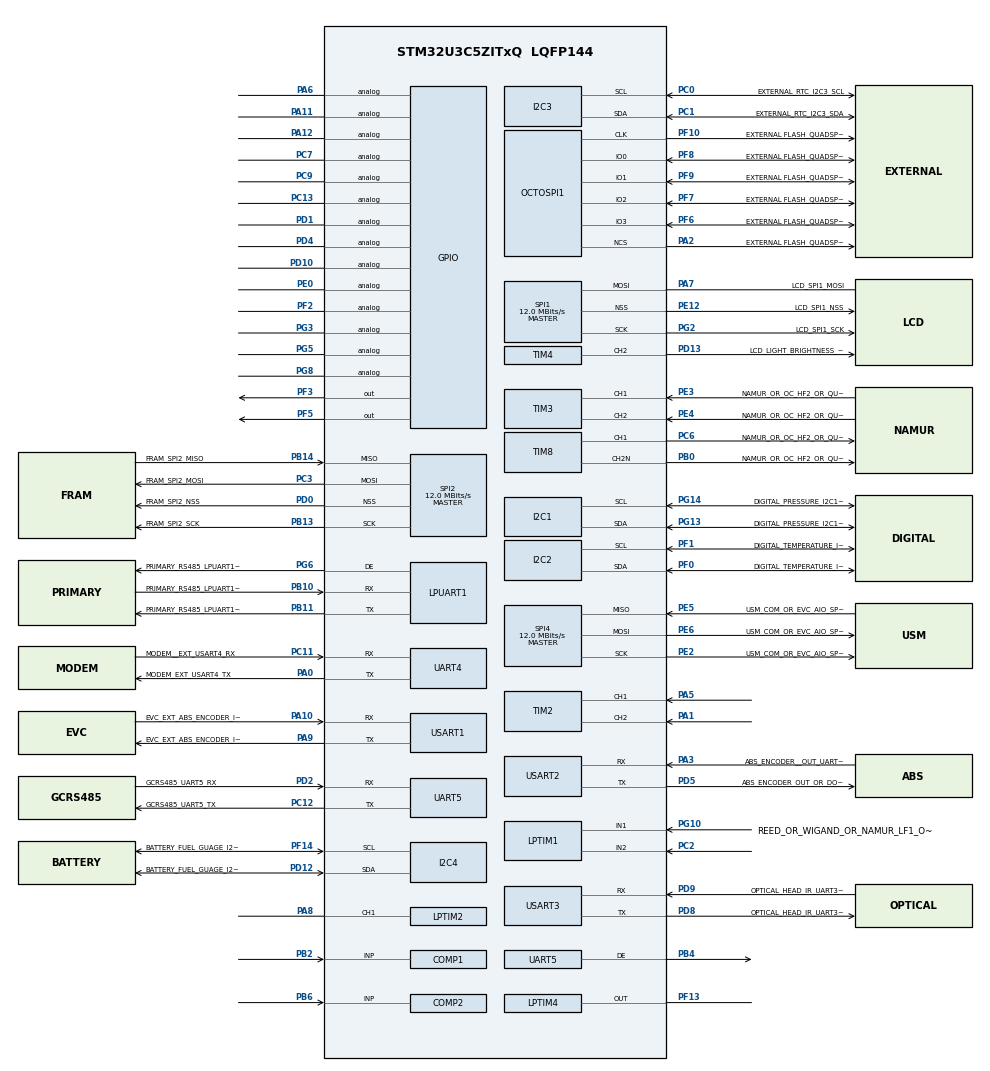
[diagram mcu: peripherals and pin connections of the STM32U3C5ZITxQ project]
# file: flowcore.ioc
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CORTEX_M33_NS.userName=CORTEX_M33
GPDMA1.LINKALLOCATEDPORT_GPDMACH0=DMA_LINK_ALLOCATED_PORT1
GPDMA1.PRIORITY_LL_GPDMACH0=DMA_HIGH_PRIORITY
I2C1.Timing=0x00506682
I2C2.Timing=0x00506682
I2C3.Timing=0x00506682
I2C4.Timing=0x00506682
LPTIM1.ULPClockPolarity=LPTIM_CLOCKPOLARITY_RISING
LPTIM1.ULPClockSampleTime=LPTIM_CLOCKSAMPLETIME_8TRANSITIONS
LPTIM2.ClockPrescaler=LPTIM_PRESCALER_DIV32
LPTIM2.ICPolarity_1=LPTIM_ICPOLARITY_RISING_FALLING
LPTIM3.ClockPrescaler=LPTIM_PRESCALER_DIV32
LPTIM3.Period=7
LPTIM3.UpdateMode=LPTIM_UPDATE_ENDOFPERIOD
Mcu.Family=STM32U3
Mcu.Name=STM32U3C5ZITxQ
Mcu.Package=LQFP144
NVIC.LPTIM2_IRQn=true\:0\:0\:false\:false\:true\:true\:true\:true
NVIC.PriorityGroup=NVIC_PRIORITYGROUP_4
NVIC.RTC_IRQn=true\:0\:0\:false\:false\:true\:true\:true\:true
OCTOSPI1.ClockMode=HAL_XSPI_CLOCK_MODE_3
OCTOSPI1.MemorySize=HAL_XSPI_SIZE_32MB
PA0.GPIO_Label=MODEM_EXT_USART4_TX
PA0.Mode=Asynchronous
PA0.Signal=UART4_TX
PA1.Signal=S_TIM2_CH2
PA10.GPIO_Label=EVC_EXT_ABS_ENCODER_INPUT_UART1_RX
PA10.Mode=Asynchronous
PA10.Signal=USART1_RX
PA11.Signal=GPIO_Analog
PA12.Signal=GPIO_Analog
PA13\ (JTMS/SWDIO).Mode=JTAG_4_pins
PA13\ (JTMS/SWDIO).Signal=DEBUG_JTMS-SWDIO
PA14\ (JTCK/SWCLK).Mode=JTAG_4_pins
PA14\ (JTCK/SWCLK).Signal=DEBUG_JTCK-SWCLK
PA15\ (JTDI).Mode=JTAG_4_pins
PA15\ (JTDI).Signal=DEBUG_JTDI
PA2.GPIO_Label=EXTERNAL FLASH_QUADSPI_BK1_NCS
PA2.Mode=quad_mode
PA2.Signal=OCTOSPI1_NCS
PA3.GPIO_Label=ABS_ENCODER__OUT_UART2_RX
PA3.Mode=Asynchronous
PA3.Signal=USART2_RX
PA5.Signal=S_TIM2_CH1
PA6.Signal=GPIO_Analog
PA7.GPIO_Label=LCD_SPI1_MOSI 
PA7.Mode=Simplex_Bidirectional_Master
PA7.Signal=SPI1_MOSI
PA8.Signal=S_LPTIM2_CH1
PA9.GPIO_Label=EVC_EXT_ABS_ENCODER_INPUT_UART1_TX
PA9.Mode=Asynchronous
PA9.Signal=USART1_TX
PB0.GPIO_Label=NAMUR_OR_OC_HF2_OR_QUAD2_S_OUTPUT_TIM8_CH1N
PB0.Mode=PWM Generation2 CH2N
PB0.Signal=TIM8_CH2N
PB10.GPIO_Label=PRIMARY_RS485_LPUART1_RX
PB10.Mode=Asynchronous
PB10.Signal=LPUART1_RX
PB11.GPIO_Label=PRIMARY_RS485_LPUART1_TX
PB11.Mode=Asynchronous
PB11.Signal=LPUART1_TX
PB13.GPIO_Label=FRAM_SPI2_SCK
PB13.Mode=Full_Duplex_Master
PB13.Signal=SPI2_SCK
PB14.GPIO_Label=FRAM_SPI2_MISO
PB14.Mode=Full_Duplex_Master
PB14.Signal=SPI2_MISO
PB2.Mode=INP
PB2.Signal=COMP1_INP
PB3\ (JTDO/TRACESWO).Mode=JTAG_4_pins
PB3\ (JTDO/TRACESWO).Signal=DEBUG_JTDO-SWO
PB4\ (NJTRST).Mode=Hardware Flow Control (RS485)
PB4\ (NJTRST).Signal=UART5_DE
PB6.Mode=INP
PB6.Signal=COMP2_INP
PC0.GPIO_Label=EXTERNAL_RTC_I2C3_SCL
PC0.Mode=I2C
PC0.Signal=I2C3_SCL
PC1.GPIO_Label=EXTERNAL_RTC_I2C3_SDA
PC1.Mode=I2C
PC1.Signal=I2C3_SDA
PC11.GPIO_Label=MODEM__EXT_USART4_RX
PC11.Mode=Asynchronous
PC11.Signal=UART4_RX
PC12.GPIO_Label=GCRS485_UART5_TX
PC12.Mode=Asynchronous
PC12.Signal=UART5_TX
PC13.Signal=GPIO_Analog
PC14-OSC32_IN\ (PC14).GPIO_Label=RCC_OSCC32_IN
PC14-OSC32_IN\ (PC14).Mode=LSE-External-Oscillator
PC14-OSC32_IN\ (PC14).Signal=RCC_OSC32_IN
PC15-OSC32_OUT\ (PC15).GPIO_Label=RCC_OSCC32_OUT
PC15-OSC32_OUT\ (PC15).Mode=LSE-External-Oscillator
PC15-OSC32_OUT\ (PC15).Signal=RCC_OSC32_OUT
PC2.GPIO_PuPd=GPIO_PULLUP
PC2.Mode=Encoder_mode_occur1
PC2.Signal=LPTIM1_IN2
PC3.GPIO_Label=FRAM_SPI2_MOSI
PC3.Mode=Full_Duplex_Master
PC3.Signal=SPI2_MOSI
PC6.GPIO_Label=NAMUR_OR_OC_HF2_OR_QUAD2_P_OUTPUT_OR_DO2_TIM8_CH1
PC6.Signal=S_TIM8_CH1
PC7.Signal=GPIO_Analog
PC9.Signal=GPIO_Analog
PD0.GPIO_Label=FRAM_SPI2_NSS
PD0.Mode=NSS_Signal_Hard_Output
PD0.Signal=SPI2_NSS
PD1.Signal=GPIO_Analog
PD10.Signal=GPIO_Analog
PD12.GPIO_Label=BATTERY_FUEL_GUAGE_I2C4_SDA
PD12.Mode=I2C
PD12.Signal=I2C4_SDA
PD13.GPIO_Label=LCD_LIGHT_BRIGHTNESS_CONTROLL_PWM_TIM4_CH2
PD13.Signal=S_TIM4_CH2
PD2.GPIO_Label=GCRS485_UART5_RX
PD2.Mode=Asynchronous
PD2.Signal=UART5_RX
PD4.Signal=GPIO_Analog
PD5.GPIO_Label=ABS_ENCODER_OUT_OR_DO3_UART2_TX
PD5.Mode=Asynchronous
PD5.Signal=USART2_TX
PD8.GPIO_Label=OPTICAL_HEAD_IR_UART3_TX
PD8.Mode=Asynchronous
PD8.Signal=USART3_TX
PD9.GPIO_Label=OPTICAL_HEAD_IR_UART3_RX_OR_IRQ_EXTI9
PD9.Mode=Asynchronous
PD9.Signal=USART3_RX
PE0.Signal=GPIO_Analog
PE12.GPIO_Label=LCD_SPI1_NSS
PE12.Mode=NSS_Signal_Hard_Output
PE12.Signal=SPI1_NSS
PE2.GPIO_Label=USM_COM_OR_EVC_AIO_SPI4_SCK
PE2.Mode=Full_Duplex_Master
PE2.Signal=SPI4_SCK
PE3.GPIO_Label=NAMUR_OR_OC_HF2_OR_QUAD2_P_INPUT_TIM3_CH1
PE3.Signal=S_TIM3_CH1
PE4.GPIO_Label=NAMUR_OR_OC_HF2_OR_QUAD2_S_INPUT_TIM3_CH2
PE4.Signal=S_TIM3_CH2
PE5.GPIO_Label=USM_COM_OR_EVC_AIO_SPI4_MISO
PE5.Mode=Full_Duplex_Master
PE5.Signal=SPI4_MISO
PE6.GPIO_Label=USM_COM_OR_EVC_AIO_SPI4_MOSI
PE6.Mode=Full_Duplex_Master
PE6.PinAttribute=Free
PE6.Signal=SPI4_MOSI
PF0.GPIO_Label=DIGITAL_TEMPERATURE_I2C2_SDA
PF0.Mode=I2C
PF0.PinAttribute=Free
PF0.Signal=I2C2_SDA
PF1.GPIO_Label=DIGITAL_TEMPERATURE_I2C2_SCL
PF1.Mode=I2C
PF1.PinAttribute=Free
PF1.Signal=I2C2_SCL
PF10.GPIO_Label=EXTERNAL FLASH_QUADSPI_CLK
PF10.Mode=quad_mode
PF10.Signal=OCTOSPI1_CLK
PF13.Mode=WaveformGeneration
PF13.Signal=LPTIM4_OUT
PF14.GPIO_Label=BATTERY_FUEL_GUAGE_I2C4_SCL
PF14.Mode=I2C
PF14.Signal=I2C4_SCL
PF2.Signal=GPIO_Analog
PF3.Signal=GPIO_Output
PF5.Signal=GPIO_Output
PF6.GPIO_Label=EXTERNAL FLASH_QUADSPI_BK1_IO3
PF6.Mode=OCTOSPI1_IO[3\:0]
PF6.Signal=OCTOSPI1_IO3
PF7.GPIO_Label=EXTERNAL FLASH_QUADSPI_BK1_IO2
PF7.Mode=OCTOSPI1_IO[3\:0]
PF7.Signal=OCTOSPI1_IO2
PF8.GPIO_Label=EXTERNAL FLASH_QUADSPI_BK1_IO0
PF8.Mode=OCTOSPI1_IO[3\:0]
PF8.Signal=OCTOSPI1_IO0
PF9.GPIO_Label=EXTERNAL FLASH_QUADSPI_BK1_IO1
PF9.Mode=OCTOSPI1_IO[3\:0]
PF9.Signal=OCTOSPI1_IO1
PG10.GPIO_Label=REED_OR_WIGAND_OR_NAMUR_LF1_OR_QUAD1_P_INPUT_LPTIM1_IN1
PG10.GPIO_PuPd=GPIO_PULLUP
PG10.Mode=Encoder_mode_occur1
PG10.Signal=LPTIM1_IN1
PG13.GPIO_Label=DIGITAL_PRESSURE_I2C1_SDA
PG13.Mode=I2C
PG13.Signal=I2C1_SDA
PG14.GPIO_Label=DIGITAL_PRESSURE_I2C1_SCL
PG14.Mode=I2C
PG14.Signal=I2C1_SCL
PG2.GPIO_Label=LCD_SPI1_SCK
PG2.Mode=Simplex_Bidirectional_Master
PG2.Signal=SPI1_SCK
PG3.Signal=GPIO_Analog
PG5.Signal=GPIO_Analog
PG6.GPIO_Label=PRIMARY_RS485_LPUART1_DE
PG6.Mode=Hardware Flow Control (RS485)
PG6.Signal=LPUART1_DE
PG8.Signal=GPIO_Analog
PH0-OSC_IN\ (PH0).Mode=HSE-External-Oscillator
PH0-OSC_IN\ (PH0).Signal=RCC_OSC_IN
PH1-OSC_OUT\ (PH1).Mode=HSE-External-Oscillator
PH1-OSC_OUT\ (PH1).Signal=RCC_OSC_OUT
ProjectManager.HeapSize=0x200
ProjectManager.StackSize=0x400
ProjectManager.TargetToolchain=STM32CubeIDE
RCC.ADCFreq_Value=24000000
RCC.AHBFreq_Value=24000000
RCC.APB1Freq_Value=24000000
RCC.APB1TimFreq_Value=24000000
RCC.APB2Freq_Value=24000000
RCC.APB2TimFreq_Value=24000000
RCC.APB3Freq_Value=24000000
RCC.CortexFreq_Value=3000000
RCC.HCLKFreq_Value=24000000
RCC.HSE_VALUE=16000000
RCC.HSI48_VALUE=48000000
RCC.HSI_VALUE=16000000
RCC.LPTIM1CLockSelection=RCC_LPTIM1CLKSOURCE_LSE
RCC.LPTIM2CLockSelection=RCC_LPTIM2CLKSOURCE_LSE
RCC.LPTIM3CLockSelection=RCC_LPTIM34CLKSOURCE_LSE
RCC.LSIDIV_VALUE=32000
RCC.MSIKSource=RCC_MSI_RC1
RCC.MSISDIV=RCC_MSI_DIV1
RCC.MSISSource=RCC_MSI_RC1
RCC.RTCClockSelection=RCC_RTCCLKSOURCE_LSE
RCC.SYSCLKFreq_VALUE=24000000
RCC.USBFreq_Value=24000000
RTC.WakeUpClock-WakeUp=RTC_WAKEUPCLOCK_CK_SPRE_16BITS
RTC.WakeUpCounter-WakeUp=29
SH.S_LPTIM2_CH1.0=LPTIM2_CH1,InputIO_CH1
SH.S_TIM2_CH1.0=TIM2_CH1,Encoder_Interface
SH.S_TIM2_CH2.0=TIM2_CH2,Encoder_Interface
SH.S_TIM3_CH1.0=TIM3_CH1,Encoder_Interface
SH.S_TIM3_CH2.0=TIM3_CH2,Encoder_Interface
SH.S_TIM4_CH2.0=TIM4_CH2,PWM Generation2 CH2
SH.S_TIM8_CH1.0=TIM8_CH1,PWM Generation1 CH1
SPI1.CalculateBaudRate=12.0 MBits/s
SPI1.DataSize=SPI_DATASIZE_8BIT
SPI1.Direction=SPI_DIRECTION_1LINE
SPI1.Mode=SPI_MODE_MASTER
SPI1.VirtualNSS=VM_NSSHARD
SPI1.VirtualType=VM_MASTER
SPI2.CalculateBaudRate=12.0 MBits/s
SPI2.Direction=SPI_DIRECTION_2LINES
SPI2.Mode=SPI_MODE_MASTER
SPI2.VirtualNSS=VM_NSSHARD
SPI2.VirtualType=VM_MASTER
SPI4.CalculateBaudRate=12.0 MBits/s
SPI4.Direction=SPI_DIRECTION_2LINES
SPI4.Mode=SPI_MODE_MASTER
SPI4.VirtualType=VM_MASTER
TIM1.AutoReloadPreload=TIM_AUTORELOAD_PRELOAD_DISABLE
TIM1.CounterMode=TIM_COUNTERMODE_UP
TIM1.PeriodNoDither=4999
TIM1.Prescaler=23
TIM1.RepetitionCounter=599
TIM4.Channel-PWM\ Generation2\ CH2=TIM_CHANNEL_2
TIM8.Channel-PWM\ Generation1\ CH1=TIM_CHANNEL_1
TIM8.Channel-PWM\ Generation2\ CH2N=TIM_CHANNEL_2
USART1.VirtualMode-Asynchronous=VM_ASYNC
USART2.VirtualMode-Asynchronous=VM_ASYNC
USART3.VirtualMode-Asynchronous=VM_ASYNC
VP_COMP1_VS_VREFINT.Mode=VREFINT
VP_COMP2_VS_VREFINT.Mode=VREFINT
VP_CORTEX_M33_NS_VS_Hclk.Mode=Hclk_Mode
VP_GPDMA1_VS_GPDMACH0.Mode=LINKEDLIST_GPDMACH0
VP_ICACHE_VS_ICACHE.Mode=DirectMappedCache
VP_LPTIM2_VS_CH1.Mode=Channel_1_Active
VP_LPTIM2_VS_LPTIM_counterModeInternalClock.Mode=Counts__internal_clock_event_00
VP_LPTIM3_VS_LPTIM_counterModeInternalClock.Mode=Counts__internal_clock_event_00
VP_LPTIM4_VS_LPTIM_counterModeInternalClock.Mode=Counts__internal_clock_event_00
VP_PWR_VS_DBSignals.Mode=DisableDeadBatterySignals
VP_PWR_VS_SECSignals.Mode=Security/Privilege
VP_RTC_VS_RTC_Activate.Mode=RTC_Enabled
VP_RTC_VS_RTC_WakeUp_intern.Mode=WakeUp
VP_TIM1_VS_ClockSourceINT.Mode=Internal
board=custom

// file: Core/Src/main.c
/* USER CODE BEGIN Header */
/**
  ******************************************************************************
  * @file           : main.c
  * @brief          : Main program body
  ******************************************************************************
  * @attention
  *
  * Copyright (c) 2026 STMicroelectronics.
  * All rights reserved.
  *
  * This software is licensed under terms that can be found in the LICENSE file
  * in the root directory of this software component.
  * If no LICENSE file comes with this software, it is provided AS-IS.
  *
  ******************************************************************************
  */
/* USER CODE END Header */
#include "main.h"

/* USER CODE BEGIN Includes */

#include "stm32u3xx_ll_tim.h"
#include "stm32u3xx_hal_dma_ex.h"
#include <stdio.h>
#include <string.h>

/* USER CODE END Includes */

/* USER CODE BEGIN PD */

#define QUAD_MAX_STEPS 512U
#define QUAD_A_PIN GPIO_PIN_5
#define QUAD_B_PIN GPIO_PIN_3
#define QUAD_PINS (QUAD_A_PIN | QUAD_B_PIN)

/* USER CODE END PD */

COMP_HandleTypeDef hcomp1;
COMP_HandleTypeDef hcomp2;

DMA_HandleTypeDef handle_GPDMA1_Channel0;

I2C_HandleTypeDef hi2c1;
I2C_HandleTypeDef hi2c2;
I2C_HandleTypeDef hi2c3;
I2C_HandleTypeDef hi2c4;

LPTIM_HandleTypeDef hlptim1;
LPTIM_HandleTypeDef hlptim2;
LPTIM_HandleTypeDef hlptim3;
LPTIM_HandleTypeDef hlptim4;

UART_HandleTypeDef hlpuart1;
UART_HandleTypeDef huart4;
UART_HandleTypeDef huart5;
UART_HandleTypeDef huart1;
UART_HandleTypeDef huart2;
UART_HandleTypeDef huart3;

XSPI_HandleTypeDef hxspi1;

RTC_HandleTypeDef hrtc;

SPI_HandleTypeDef hspi1;
SPI_HandleTypeDef hspi2;
SPI_HandleTypeDef hspi4;

TIM_HandleTypeDef htim1;
TIM_HandleTypeDef htim2;
TIM_HandleTypeDef htim3;
TIM_HandleTypeDef htim4;
TIM_HandleTypeDef htim8;

/* USER CODE BEGIN PV */

static volatile uint8_t lf_wakeup;
enum {
    LF_TICK_HZ = 1024U,
    LF_MIN_HIGH_TICKS = (40U * LF_TICK_HZ) / 1000U,
    LF_MIN_LOW_TICKS = (60U * LF_TICK_HZ) / 1000U,
    LF_REPORT_SECONDS = 30U
};

typedef struct {
    uint32_t edges;
    uint32_t valid;
    uint32_t noise;
    uint32_t early;
    uint32_t lost;
    uint32_t periods;
    uint32_t period_ticks;
    uint32_t irq_entries;
} LF_Window;

static volatile LF_Window lf_window;
static uint16_t lf_rise, lf_fall, lf_previous_rise;
static uint8_t lf_have_rise, lf_have_fall, lf_have_previous_rise;

// static DMA_HandleTypeDef quad_dma;
static DMA_QListTypeDef quad_queue;

/* DMA nodes must remain inside one 64-Kbyte address window. */
static DMA_NodeTypeDef quad_nodes[2U * QUAD_MAX_STEPS + 1U]
    __attribute__((aligned(65536)));

static uint32_t quad_words[QUAD_MAX_STEPS];
static uint32_t quad_arr = 7U;
static uint32_t quad_stop = 0U;
static uint8_t quad_phase;

_Static_assert(sizeof(quad_nodes) <= 65536U,
               "DMA nodes exceed 64-Kbyte window");

/* USER CODE END PV */

void SystemClock_Config(void);
static void MX_GPIO_Init(void);
static void MX_GPDMA1_Init(void);
static void MX_I2C1_Init(void);
static void MX_I2C2_Init(void);
static void MX_I2C3_Init(void);
static void MX_LPUART1_UART_Init(void);
static void MX_UART4_Init(void);
static void MX_UART5_Init(void);
static void MX_USART1_UART_Init(void);
static void MX_USART2_UART_Init(void);
static void MX_USART3_UART_Init(void);
static void MX_OCTOSPI1_Init(void);
static void MX_SPI1_Init(void);
static void MX_SPI2_Init(void);
static void MX_SPI4_Init(void);
static void MX_LPTIM1_Init(void);
static void MX_LPTIM3_Init(void);
static void MX_I2C4_Init(void);
static void MX_ICACHE_Init(void);
static void MX_RTC_Init(void);
static void MX_COMP1_Init(void);
static void MX_COMP2_Init(void);
static void MX_LPTIM4_Init(void);
static void MX_TIM1_Init(void);
static void MX_TIM2_Init(void);
static void MX_TIM3_Init(void);
static void MX_TIM8_Init(void);
static void MX_TIM4_Init(void);
static void MX_LPTIM2_Init(void);

/* USER CODE BEGIN 0 */

static void LF_Print(const char *text)
{
    if (HAL_UART_Transmit(&huart1, (const uint8_t *)text,
                          (uint16_t)strlen(text), 100U) != HAL_OK)
    {
        Error_Handler();
    }
}

static void LF_StartCapture(void)
{
    __HAL_RCC_GPIOA_CLK_SLEEP_ENABLE();
    __HAL_RCC_LPTIM2_CLK_SLEEP_ENABLE();

    __HAL_RCC_GPIOA_CLK_STOP_ENABLE();
    __HAL_RCC_LPTIM2_CLK_STOP_ENABLE();

    if (HAL_LPTIM_IC_Start_IT(&hlptim2, LPTIM_CHANNEL_1) != HAL_OK)
    {
        Error_Handler();
    }
}

static void LF_ResetPairing(void)
{
    lf_have_rise = 0U;
    lf_have_fall = 0U;
    lf_have_previous_rise = 0U;
}

static void LF_RecordEdge(uint16_t stamp, uint8_t high_level)
{
    ++lf_window.edges;

    if (high_level != 0U)
    {
        if (lf_have_rise != 0U)
        {
            ++lf_window.lost;
            LF_ResetPairing();
        }

        lf_rise = stamp;
        lf_have_rise = 1U;
        return;
    }

    if (lf_have_rise != 0U)
    {
        uint16_t high = (uint16_t)(stamp - lf_rise);
        uint16_t low = (uint16_t)(lf_rise - lf_fall);
        uint8_t short_pulse = (high < LF_MIN_HIGH_TICKS);
        uint8_t early_pulse = (lf_have_fall != 0U && low < LF_MIN_LOW_TICKS);

        lf_window.noise += short_pulse;
        lf_window.early += early_pulse;

        if (short_pulse == 0U && early_pulse == 0U)
        {
            ++lf_window.valid;
            if (lf_have_previous_rise != 0U)
            {
                lf_window.period_ticks += (uint16_t)(lf_rise - lf_previous_rise);
                ++lf_window.periods;
            }
            lf_previous_rise = lf_rise;
            lf_have_previous_rise = 1U;
        }
        else
        {
            lf_have_previous_rise = 0U;
        }
    }
    else if (lf_have_fall != 0U)
    {
        ++lf_window.lost;
        LF_ResetPairing();
    }

    lf_have_rise = 0U;
    lf_fall = stamp;
    lf_have_fall = 1U;
}

void LF_HandleCaptureIRQ(void)
{
    ++lf_window.irq_entries;
    uint32_t flags = LPTIM2->ISR;
    if ((flags & LPTIM_FLAG_CC1) == 0U)
    {
        return;
    }

    uint16_t stamp = (uint16_t)LPTIM2->CCR1;
    uint8_t high_level = ((GPIOA->IDR & GPIO_PIN_8) != 0U);
    uint32_t after = LPTIM2->ISR;

    if (((flags | after) & LPTIM_FLAG_CC1O) != 0U ||
        (after & LPTIM_FLAG_CC1) != 0U)
    {
        LPTIM2->ICR = LPTIM_FLAG_CC1O;
        ++lf_window.lost;
        LF_ResetPairing();
        return;
    }

    LF_RecordEdge(stamp, high_level);
}

static void LF_Report(void)
{
    __disable_irq();
    LF_Window window = lf_window;
    lf_window = (LF_Window){0};
    lf_wakeup = 0U;

    if (window.edges == 0U)
    {
        LF_ResetPairing();
    }
    __enable_irq();

    if (window.edges == 0U && window.lost == 0U)
    {
        LF_Print("LF_FAULT: NO_EDGES\r\n");
    }

    uint32_t millihz = window.period_ticks == 0U ? 0U :
        (1000U * LF_TICK_HZ * window.periods + window.period_ticks / 2U) /
        window.period_ticks;
    char message[120];

    snprintf(message, sizeof(message),
            //  "LF Valid=%lu Noise=%lu EARLY_PULSE=%lu CAPTURE_LOSS=%lu Freq=%lu.%03lu Hz\r\n",
             "30 sec passed | LF Valid=%lu Noise=%lu EARLY_PULSE=%lu "
            "CAPTURE_LOSS=%lu Freq=%lu.%03lu Hz\r\n",
             (unsigned long)window.valid, (unsigned long)window.noise,
             (unsigned long)window.early, (unsigned long)window.lost,
             (unsigned long)(millihz / 1000U), (unsigned long)(millihz % 1000U));

    LF_Print(message);

    static uint16_t previous_cnt;
    uint16_t cnt = (uint16_t)LPTIM2->CNT;
    uint16_t delta = (uint16_t)(cnt - previous_cnt);
    previous_cnt = cnt;

    snprintf(message, sizeof(message),
            "LF debug: IRQ=%lu Edges=%lu CNTdelta=%u CC1E=%u CC1IE=%u\r\n",
            (unsigned long)window.irq_entries, (unsigned long)window.edges,
            (unsigned)delta,
            (unsigned)((LPTIM2->CCMR1 & LPTIM_CCMR1_CC1E) != 0U),
            (unsigned)((LPTIM2->DIER & LPTIM_DIER_CC1IE) != 0U));
    // LF_Print(message);
    LF_Print(message);
}

static void QUAD_Init(void)
{
    GPIO_InitTypeDef gpio = {0};

    if (hlptim3.Init.CounterSource != LPTIM_COUNTERSOURCE_INTERNAL ||
        hlptim3.Init.Clock.Prescaler != LPTIM_PRESCALER_DIV32 ||
        hlptim3.Init.Period != quad_arr ||
        hlptim3.Init.RepetitionCounter != 0U)
    {
        LF_Print("Check LPTIM3: internal clock, DIV32, ARR=7, RCR=0\r\n");
        Error_Handler();
    }

    __HAL_RCC_GPIOF_CLK_ENABLE();

    /* Set the initial A/B state to 00. */
    HAL_GPIO_WritePin(GPIOF, QUAD_PINS, GPIO_PIN_RESET);

    gpio.Pin = QUAD_PINS;
    gpio.Mode = GPIO_MODE_OUTPUT_PP;
    gpio.Pull = GPIO_NOPULL;
    gpio.Speed = GPIO_SPEED_FREQ_LOW;
    HAL_GPIO_Init(GPIOF, &gpio);

    // __HAL_RCC_GPDMA1_CLK_ENABLE();
    __HAL_RCC_GPDMA1_CLK_SLEEP_ENABLE();
    __HAL_RCC_SRAM1_CLK_SLEEP_ENABLE();
    __HAL_RCC_GPIOF_CLK_SLEEP_ENABLE();
    __HAL_RCC_LPTIM1_CLK_SLEEP_ENABLE();
    __HAL_RCC_LPTIM3_CLK_SLEEP_ENABLE();

    // HAL_NVIC_DisableIRQ(GPDMA1_Channel0_IRQn);

    quad_phase = 0U;

}

static void QUAD_AddNode(uint32_t index, uint32_t request,
                         uint32_t *source,
                         volatile uint32_t *destination)
{
    DMA_NodeConfTypeDef cfg = {0};

    cfg.NodeType = DMA_GPDMA_LINEAR_NODE;
    cfg.Init.Request = request;
    cfg.Init.BlkHWRequest = (request == DMA_REQUEST_SW)
                           ? DMA_BREQ_SINGLE_BURST : DMA_BREQ_BLOCK;
    cfg.Init.Direction = (request == DMA_REQUEST_SW)
                         ? DMA_MEMORY_TO_MEMORY : DMA_MEMORY_TO_PERIPH;
    cfg.Init.SrcInc = DMA_SINC_FIXED;
    cfg.Init.DestInc = DMA_DINC_FIXED;
    cfg.Init.SrcDataWidth = DMA_SRC_DATAWIDTH_WORD;
    cfg.Init.DestDataWidth = DMA_DEST_DATAWIDTH_WORD;
    cfg.Init.SrcBurstLength = 1U;
    cfg.Init.DestBurstLength = 1U;
    cfg.Init.TransferAllocatedPort =
        DMA_SRC_ALLOCATED_PORT1 | DMA_DEST_ALLOCATED_PORT0;
    cfg.Init.TransferEventMode = DMA_TCEM_LAST_LL_ITEM_TRANSFER;
    cfg.Init.Mode = DMA_NORMAL;

    cfg.TriggerConfig.TriggerPolarity = DMA_TRIG_POLARITY_MASKED;
    cfg.SrcAddress = (uint32_t)source;
    cfg.DstAddress = (uint32_t)destination;
    cfg.DataSize = sizeof(uint32_t);

    if (HAL_DMAEx_List_BuildNode(&cfg, &quad_nodes[index]) != HAL_OK)
    {
        Error_Handler();
    }

    /* The local HAL node builder omits this field: apply BREQ explicitly. */
    quad_nodes[index].LinkRegisters[NODE_CTR2_DEFAULT_OFFSET] |=
        cfg.Init.BlkHWRequest;

    if (HAL_DMAEx_List_InsertNode_Tail(&quad_queue,
                                      &quad_nodes[index]) != HAL_OK)
    {
        Error_Handler();
    }
}

static void QUAD_FinishReplay(uint32_t steps)
{
    DMA_HandleTypeDef *dma = &handle_GPDMA1_Channel0;
    uint32_t timeout_ms = steps * 8U + 50U;
    HAL_StatusTypeDef status =
        HAL_DMA_PollForTransfer(dma, HAL_DMA_FULL_TRANSFER, timeout_ms);
    uint32_t error = HAL_DMA_GetError(dma);

    if (status != HAL_OK || error != HAL_DMA_ERROR_NONE)
    {
        /* Channel 0 is the only configured GPDMA1 channel. */
        if (HAL_DMA_GetState(dma) != HAL_DMA_STATE_READY)
        {
            __HAL_RCC_GPDMA1_FORCE_RESET();
            __HAL_RCC_GPDMA1_RELEASE_RESET();
            MX_GPDMA1_Init();
        }

        __HAL_RCC_LPTIM3_FORCE_RESET();
        __HAL_RCC_LPTIM3_RELEASE_RESET();
        MX_LPTIM3_Init();

        HAL_GPIO_WritePin(GPIOF, QUAD_PINS, GPIO_PIN_RESET);
        quad_phase = 0U;

        char message[72];
        snprintf(message, sizeof(message),
                 "Output replay failed in Run mode (DMA ERR=%08lX)\r\n",
                 (unsigned long)error);
        LF_Print(message);
    }

    if (HAL_DMAEx_List_UnLinkQ(dma) != HAL_OK)
    {
        Error_Handler();
    }
}

static void QUAD_SetDMA(uint32_t requests)
{
    __HAL_LPTIM_CLEAR_FLAG(&hlptim3, LPTIM_FLAG_DIEROK);
    WRITE_REG(LPTIM3->DIER, requests);

    uint32_t started = HAL_GetTick();

    while (__HAL_LPTIM_GET_FLAG(&hlptim3,
                                LPTIM_FLAG_DIEROK) == RESET)
    {
        if ((uint32_t)(HAL_GetTick() - started) > 10U)
        {
            LF_Print("LPTIM3 DMA configuration timeout\r\n");
            Error_Handler();
        }
    }
}

static void QUAD_Start(int32_t delta)
{
    static const uint32_t states[4] =
        {0U, QUAD_A_PIN, QUAD_PINS, QUAD_B_PIN};

    uint32_t steps = (delta < 0)
                     ? (uint32_t)(-delta) : (uint32_t)delta;
    uint8_t phase = quad_phase;
    uint32_t index = 0U;

    if (steps == 0U)
    {
        return;
    }

    if (steps > QUAD_MAX_STEPS)
    {
        LF_Print("Replay skipped: more than 512 counts\r\n");
        return;
    }

    if (HAL_LPTIM_Counter_Stop(&hlptim3) != HAL_OK ||
        HAL_DMAEx_List_ResetQ(&quad_queue) != HAL_OK)
    {
        Error_Handler();
    }

    __HAL_LPTIM_ENABLE(&hlptim3);
    QUAD_SetDMA(0U);

    for (uint32_t i = 0U; i < steps; i++)
    {
        phase = (uint8_t)((phase +
                         ((delta > 0) ? 1U : 3U)) & 3U);

        uint32_t state = states[phase];

        /* Update only the two quadrature GPIO pins. */
        quad_words[i] = state |
                        ((QUAD_PINS & ~state) << 16U);

        /* Advance one quadrature state on a timer update. */
        QUAD_AddNode(index++, GPDMA1_REQUEST_LPTIM3_UE,
                     &quad_words[i], &GPIOF->BSRR);

        /* Re-arm the next LPTIM update DMA request. */
        QUAD_AddNode(index++, DMA_REQUEST_SW,
                     &quad_arr, &LPTIM3->ARR);
    }

    /* Stop LPTIM3 after the final state without waking the CPU. */
    QUAD_AddNode(index, DMA_REQUEST_SW,
                 &quad_stop, &LPTIM3->CR);

    if (HAL_DMAEx_List_LinkQ(&handle_GPDMA1_Channel0, &quad_queue) != HAL_OK)
    {
        Error_Handler();
    }

    __HAL_LPTIM_CLEAR_FLAG(&hlptim3, LPTIM_FLAG_UPDATE);
    __DSB();

    if (HAL_DMAEx_List_Start(&handle_GPDMA1_Channel0) != HAL_OK)
    {
        Error_Handler();
    }

    QUAD_SetDMA(LPTIM_DMA_UPDATE);

    if (HAL_LPTIM_Counter_Start(&hlptim3) != HAL_OK)
    {
        Error_Handler();
    }

    quad_phase = phase;
    QUAD_FinishReplay(steps);
}

static void LF_EnterStop1(void)
{
    HAL_SuspendTick();
    __disable_irq();
    SCB->ICSR = SCB_ICSR_PENDSTCLR_Msk;

    if (lf_wakeup == 0U)
    {
        __DSB();
        HAL_PWR_EnterSTOPMode(PWR_LOWPOWERMODE_STOP1, PWR_STOPENTRY_WFI);
    }

    __enable_irq();
    HAL_ResumeTick();
}

void HAL_RTCEx_WakeUpTimerEventCallback(RTC_HandleTypeDef *rtc)
{
    if (rtc->Instance == RTC)
    {
        lf_wakeup = 1U;
    }
}

/* USER CODE END 0 */

int main(void)
{

  /* MCU Configuration--------------------------------------------------------*/

  /* Reset of all peripherals, Initializes the Flash interface and the Systick. */
  HAL_Init();

  /* Configure the system clock */
  SystemClock_Config();

  /* Initialize all configured peripherals */
  MX_GPIO_Init();
  MX_GPDMA1_Init();
  MX_I2C1_Init();
  MX_I2C2_Init();
  MX_I2C3_Init();
  MX_LPUART1_UART_Init();
  MX_UART4_Init();
  MX_UART5_Init();
  MX_USART1_UART_Init();
  MX_USART2_UART_Init();
  MX_USART3_UART_Init();
  MX_OCTOSPI1_Init();
  MX_SPI1_Init();
  MX_SPI2_Init();
  MX_SPI4_Init();
  MX_LPTIM1_Init();
  MX_LPTIM3_Init();
  MX_I2C4_Init();
  MX_ICACHE_Init();
  MX_RTC_Init();
  MX_COMP1_Init();
  MX_COMP2_Init();
  MX_LPTIM4_Init();
  MX_TIM1_Init();
  MX_TIM2_Init();
  MX_TIM3_Init();
  MX_TIM8_Init();
  MX_TIM4_Init();
  MX_LPTIM2_Init();
  /* USER CODE BEGIN 2 */

  const uint32_t capture_configured_ms = HAL_GetTick();
  uint8_t capture_started = 0U;

  if (HAL_RTCEx_DeactivateWakeUpTimer(&hrtc) != HAL_OK)
  {
      Error_Handler();
  }

  HAL_RCCEx_StopWakeupSysclkConfig(RCC_STOP_WKUP_SYSCLK_MSIS);
  // LF_StartCapture();
  lf_wakeup = 0U;

  if (HAL_RTCEx_SetWakeUpTimer_IT(&hrtc, LF_REPORT_SECONDS - 1U,
          RTC_WAKEUPCLOCK_CK_SPRE_16BITS, 0U) != HAL_OK)
  {
      Error_Handler();
  }

  // LF_Print("LF interrupt capture armed\r\n");

  /* USER CODE END 2 */

  /* Infinite loop */
  while (1)
  {

    /* USER CODE BEGIN 3 */

    if (capture_started == 0U)
    {
        if ((HAL_GetTick() - capture_configured_ms) < 4U)
        {
            HAL_PWR_EnterSLEEPMode(PWR_MAINREGULATOR_ON, PWR_SLEEPENTRY_WFI);
            continue;
        }

        LF_StartCapture();
        capture_started = 1U;
        LF_Print("LF interrupt capture armed\r\n");
    }

    // LF_EnterStop1();
    // HAL_PWR_EnterSLEEPMode(PWR_MAINREGULATOR_ON, PWR_SLEEPENTRY_WFI);
    LF_EnterStop1();

    if (lf_wakeup != 0U)
    {
        LF_Report();
    }

    /* USER CODE END 3 */
  }
}

void SystemClock_Config(void)
{
  RCC_OscInitTypeDef RCC_OscInitStruct = {0};
  RCC_ClkInitTypeDef RCC_ClkInitStruct = {0};

  /** Configure the System Power Supply
  */
  if (HAL_PWREx_ConfigSupply(PWR_SMPS_SUPPLY) != HAL_OK)
  {
    Error_Handler();
  }

  /** Configure the main internal regulator output voltage
  */
  if (HAL_PWREx_ControlVoltageScaling(PWR_REGULATOR_VOLTAGE_SCALE2) != HAL_OK)
  {
    Error_Handler();
  }

  /** Configure LSE Drive Capability
  */
  HAL_PWR_EnableBkUpAccess();
  __HAL_RCC_LSEDRIVE_CONFIG(RCC_LSEDRIVE_LOW);

  /** Initializes the CPU, AHB and APB buses clocks
  */
  RCC_OscInitStruct.OscillatorType = RCC_OSCILLATORTYPE_LSE|RCC_OSCILLATORTYPE_MSIS;
  RCC_OscInitStruct.LSEState = RCC_LSE_ON;
  RCC_OscInitStruct.MSISState = RCC_MSI_ON;
  RCC_OscInitStruct.MSISSource = RCC_MSI_RC1;
  RCC_OscInitStruct.MSISDiv = RCC_MSI_DIV1;
  if (HAL_RCC_OscConfig(&RCC_OscInitStruct) != HAL_OK)
  {
    Error_Handler();
  }

  /** Initializes the CPU, AHB and APB buses clocks
  */
  RCC_ClkInitStruct.ClockType = RCC_CLOCKTYPE_HCLK|RCC_CLOCKTYPE_SYSCLK
                              |RCC_CLOCKTYPE_PCLK1|RCC_CLOCKTYPE_PCLK2
                              |RCC_CLOCKTYPE_PCLK3;
  RCC_ClkInitStruct.SYSCLKSource = RCC_SYSCLKSOURCE_MSIS;
  RCC_ClkInitStruct.AHBCLKDivider = RCC_SYSCLK_DIV1;
  RCC_ClkInitStruct.APB1CLKDivider = RCC_HCLK_DIV1;
  RCC_ClkInitStruct.APB2CLKDivider = RCC_HCLK_DIV1;
  RCC_ClkInitStruct.APB3CLKDivider = RCC_HCLK_DIV1;

  if (HAL_RCC_ClockConfig(&RCC_ClkInitStruct, FLASH_LATENCY_1) != HAL_OK)
  {
    Error_Handler();
  }
}

static void MX_COMP1_Init(void)
{

  hcomp1.Instance = COMP1;
  hcomp1.Init.InputPlus = COMP_INPUT_PLUS_IO2;
  hcomp1.Init.InputMinus = COMP_INPUT_MINUS_VREFINT;
  hcomp1.Init.OutputPol = COMP_OUTPUTPOL_NONINVERTED;
  hcomp1.Init.WindowOutput = COMP_WINDOWOUTPUT_EACH_COMP;
  hcomp1.Init.Hysteresis = COMP_HYSTERESIS_NONE;
  hcomp1.Init.BlankingSrce = COMP_BLANKINGSRC_NONE;
  hcomp1.Init.Mode = COMP_POWERMODE_HIGHSPEED;
  hcomp1.Init.WindowMode = COMP_WINDOWMODE_DISABLE;
  hcomp1.Init.TriggerMode = COMP_TRIGGERMODE_NONE;
  if (HAL_COMP_Init(&hcomp1) != HAL_OK)
  {
    Error_Handler();
  }

}

static void MX_COMP2_Init(void)
{

  hcomp2.Instance = COMP2;
  hcomp2.Init.InputPlus = COMP_INPUT_PLUS_IO2;
  hcomp2.Init.InputMinus = COMP_INPUT_MINUS_VREFINT;
  hcomp2.Init.OutputPol = COMP_OUTPUTPOL_NONINVERTED;
  hcomp2.Init.WindowOutput = COMP_WINDOWOUTPUT_EACH_COMP;
  hcomp2.Init.Hysteresis = COMP_HYSTERESIS_NONE;
  hcomp2.Init.BlankingSrce = COMP_BLANKINGSRC_NONE;
  hcomp2.Init.Mode = COMP_POWERMODE_HIGHSPEED;
  hcomp2.Init.WindowMode = COMP_WINDOWMODE_DISABLE;
  hcomp2.Init.TriggerMode = COMP_TRIGGERMODE_NONE;
  if (HAL_COMP_Init(&hcomp2) != HAL_OK)
  {
    Error_Handler();
  }

}

static void MX_GPDMA1_Init(void)
{

  /* Peripheral clock enable */
  __HAL_RCC_GPDMA1_CLK_ENABLE();

  handle_GPDMA1_Channel0.Instance = GPDMA1_Channel0;
  handle_GPDMA1_Channel0.InitLinkedList.Priority = DMA_HIGH_PRIORITY;
  handle_GPDMA1_Channel0.InitLinkedList.LinkStepMode = DMA_LSM_FULL_EXECUTION;
  handle_GPDMA1_Channel0.InitLinkedList.LinkAllocatedPort = DMA_LINK_ALLOCATED_PORT1;
  handle_GPDMA1_Channel0.InitLinkedList.TransferEventMode = DMA_TCEM_LAST_LL_ITEM_TRANSFER;
  handle_GPDMA1_Channel0.InitLinkedList.LinkedListMode = DMA_LINKEDLIST_NORMAL;
  if (HAL_DMAEx_List_Init(&handle_GPDMA1_Channel0) != HAL_OK)
  {
    Error_Handler();
  }
  if (HAL_DMA_ConfigChannelAttributes(&handle_GPDMA1_Channel0, DMA_CHANNEL_NPRIV) != HAL_OK)
  {
    Error_Handler();
  }

}

static void MX_I2C1_Init(void)
{

  hi2c1.Instance = I2C1;
  hi2c1.Init.Timing = 0x00506682;
  hi2c1.Init.OwnAddress1 = 0;
  hi2c1.Init.AddressingMode = I2C_ADDRESSINGMODE_7BIT;
  hi2c1.Init.DualAddressMode = I2C_DUALADDRESS_DISABLE;
  hi2c1.Init.OwnAddress2 = 0;
  hi2c1.Init.OwnAddress2Masks = I2C_OA2_NOMASK;
  hi2c1.Init.GeneralCallMode = I2C_GENERALCALL_DISABLE;
  hi2c1.Init.NoStretchMode = I2C_NOSTRETCH_DISABLE;
  if (HAL_I2C_Init(&hi2c1) != HAL_OK)
  {
    Error_Handler();
  }

  /** Configure Analogue filter
  */
  if (HAL_I2CEx_ConfigAnalogFilter(&hi2c1, I2C_ANALOGFILTER_ENABLE) != HAL_OK)
  {
    Error_Handler();
  }

  /** Configure Digital filter
  */
  if (HAL_I2CEx_ConfigDigitalFilter(&hi2c1, 0) != HAL_OK)
  {
    Error_Handler();
  }

}

static void MX_I2C2_Init(void)
{

  hi2c2.Instance = I2C2;
  hi2c2.Init.Timing = 0x00506682;
  hi2c2.Init.OwnAddress1 = 0;
  hi2c2.Init.AddressingMode = I2C_ADDRESSINGMODE_7BIT;
  hi2c2.Init.DualAddressMode = I2C_DUALADDRESS_DISABLE;
  hi2c2.Init.OwnAddress2 = 0;
  hi2c2.Init.OwnAddress2Masks = I2C_OA2_NOMASK;
  hi2c2.Init.GeneralCallMode = I2C_GENERALCALL_DISABLE;
  hi2c2.Init.NoStretchMode = I2C_NOSTRETCH_DISABLE;
  if (HAL_I2C_Init(&hi2c2) != HAL_OK)
  {
    Error_Handler();
  }

  /** Configure Analogue filter
  */
  if (HAL_I2CEx_ConfigAnalogFilter(&hi2c2, I2C_ANALOGFILTER_ENABLE) != HAL_OK)
  {
    Error_Handler();
  }

  /** Configure Digital filter
  */
  if (HAL_I2CEx_ConfigDigitalFilter(&hi2c2, 0) != HAL_OK)
  {
    Error_Handler();
  }

}

static void MX_I2C3_Init(void)
{

  hi2c3.Instance = I2C3;
  hi2c3.Init.Timing = 0x00506682;
  hi2c3.Init.OwnAddress1 = 0;
  hi2c3.Init.AddressingMode = I2C_ADDRESSINGMODE_7BIT;
  hi2c3.Init.DualAddressMode = I2C_DUALADDRESS_DISABLE;
  hi2c3.Init.OwnAddress2 = 0;
  hi2c3.Init.OwnAddress2Masks = I2C_OA2_NOMASK;
  hi2c3.Init.GeneralCallMode = I2C_GENERALCALL_DISABLE;
  hi2c3.Init.NoStretchMode = I2C_NOSTRETCH_DISABLE;
  if (HAL_I2C_Init(&hi2c3) != HAL_OK)
  {
    Error_Handler();
  }

  /** Configure Analogue filter
  */
  if (HAL_I2CEx_ConfigAnalogFilter(&hi2c3, I2C_ANALOGFILTER_ENABLE) != HAL_OK)
  {
    Error_Handler();
  }

  /** Configure Digital filter
  */
  if (HAL_I2CEx_ConfigDigitalFilter(&hi2c3, 0) != HAL_OK)
  {
    Error_Handler();
  }

}

static void MX_I2C4_Init(void)
{

  hi2c4.Instance = I2C4;
  hi2c4.Init.Timing = 0x00506682;
  hi2c4.Init.OwnAddress1 = 0;
  hi2c4.Init.AddressingMode = I2C_ADDRESSINGMODE_7BIT;
  hi2c4.Init.DualAddressMode = I2C_DUALADDRESS_DISABLE;
  hi2c4.Init.OwnAddress2 = 0;
  hi2c4.Init.OwnAddress2Masks = I2C_OA2_NOMASK;
  hi2c4.Init.GeneralCallMode = I2C_GENERALCALL_DISABLE;
  hi2c4.Init.NoStretchMode = I2C_NOSTRETCH_DISABLE;
  if (HAL_I2C_Init(&hi2c4) != HAL_OK)
  {
    Error_Handler();
  }

  /** Configure Analogue filter
  */
  if (HAL_I2CEx_ConfigAnalogFilter(&hi2c4, I2C_ANALOGFILTER_ENABLE) != HAL_OK)
  {
    Error_Handler();
  }

  /** Configure Digital filter
  */
  if (HAL_I2CEx_ConfigDigitalFilter(&hi2c4, 0) != HAL_OK)
  {
    Error_Handler();
  }

}

static void MX_ICACHE_Init(void)
{

  /** Enable instruction cache in 1-way (direct mapped cache)
  */
  if (HAL_ICACHE_ConfigAssociativityMode(ICACHE_1WAY) != HAL_OK)
  {
    Error_Handler();
  }
  if (HAL_ICACHE_Enable() != HAL_OK)
  {
    Error_Handler();
  }

}

static void MX_LPTIM1_Init(void)
{

  hlptim1.Instance = LPTIM1;
  hlptim1.Init.Clock.Source = LPTIM_CLOCKSOURCE_APBCLOCK_LPOSC;
  hlptim1.Init.Clock.Prescaler = LPTIM_PRESCALER_DIV1;
  hlptim1.Init.UltraLowPowerClock.Polarity = LPTIM_CLOCKPOLARITY_RISING;
  hlptim1.Init.UltraLowPowerClock.SampleTime = LPTIM_CLOCKSAMPLETIME_8TRANSITIONS;
  hlptim1.Init.Trigger.Source = LPTIM_TRIGSOURCE_SOFTWARE;
  hlptim1.Init.Period = 65535;
  hlptim1.Init.UpdateMode = LPTIM_UPDATE_IMMEDIATE;
  hlptim1.Init.CounterSource = LPTIM_COUNTERSOURCE_EXTERNAL;
  hlptim1.Init.Input1Source = LPTIM_INPUT1SOURCE_GPIO;
  hlptim1.Init.RepetitionCounter = 0;
  if (HAL_LPTIM_Init(&hlptim1) != HAL_OK)
  {
    Error_Handler();
  }

}

static void MX_LPTIM2_Init(void)
{

  LPTIM_IC_ConfigTypeDef sConfig = {0};

  hlptim2.Instance = LPTIM2;
  hlptim2.Init.Clock.Source = LPTIM_CLOCKSOURCE_APBCLOCK_LPOSC;
  hlptim2.Init.Clock.Prescaler = LPTIM_PRESCALER_DIV32;
  hlptim2.Init.Trigger.Source = LPTIM_TRIGSOURCE_SOFTWARE;
  hlptim2.Init.Period = 65535;
  hlptim2.Init.UpdateMode = LPTIM_UPDATE_IMMEDIATE;
  hlptim2.Init.CounterSource = LPTIM_COUNTERSOURCE_INTERNAL;
  hlptim2.Init.Input1Source = LPTIM_INPUT1SOURCE_GPIO;
  hlptim2.Init.RepetitionCounter = 0;
  if (HAL_LPTIM_Init(&hlptim2) != HAL_OK)
  {
    Error_Handler();
  }
  sConfig.ICInputSource = LPTIM_IC1SOURCE_GPIO;
  sConfig.ICPrescaler = LPTIM_ICPSC_DIV1;
  sConfig.ICPolarity = LPTIM_ICPOLARITY_RISING_FALLING;
  sConfig.ICFilter = LPTIM_ICFLT_CLOCK_DIV1;
  if (HAL_LPTIM_IC_ConfigChannel(&hlptim2, &sConfig, LPTIM_CHANNEL_1) != HAL_OK)
  {
    Error_Handler();
  }

}

static void MX_LPTIM3_Init(void)
{

  hlptim3.Instance = LPTIM3;
  hlptim3.Init.Clock.Source = LPTIM_CLOCKSOURCE_APBCLOCK_LPOSC;
  hlptim3.Init.Clock.Prescaler = LPTIM_PRESCALER_DIV32;
  hlptim3.Init.Trigger.Source = LPTIM_TRIGSOURCE_SOFTWARE;
  hlptim3.Init.Period = 7;
  hlptim3.Init.UpdateMode = LPTIM_UPDATE_ENDOFPERIOD;
  hlptim3.Init.CounterSource = LPTIM_COUNTERSOURCE_INTERNAL;
  hlptim3.Init.Input1Source = LPTIM_INPUT1SOURCE_GPIO;
  hlptim3.Init.RepetitionCounter = 0;
  if (HAL_LPTIM_Init(&hlptim3) != HAL_OK)
  {
    Error_Handler();
  }

}

static void MX_LPTIM4_Init(void)
{

  LPTIM_OC_ConfigTypeDef sConfig1 = {0};

  hlptim4.Instance = LPTIM4;
  hlptim4.Init.Clock.Source = LPTIM_CLOCKSOURCE_APBCLOCK_LPOSC;
  hlptim4.Init.Clock.Prescaler = LPTIM_PRESCALER_DIV1;
  hlptim4.Init.Trigger.Source = LPTIM_TRIGSOURCE_SOFTWARE;
  hlptim4.Init.Period = 65535;
  hlptim4.Init.UpdateMode = LPTIM_UPDATE_IMMEDIATE;
  hlptim4.Init.CounterSource = LPTIM_COUNTERSOURCE_INTERNAL;
  hlptim4.Init.Input1Source = LPTIM_INPUT1SOURCE_GPIO;
  hlptim4.Init.RepetitionCounter = 0;
  if (HAL_LPTIM_Init(&hlptim4) != HAL_OK)
  {
    Error_Handler();
  }
  sConfig1.Pulse = 0;
  sConfig1.OCPolarity = LPTIM_OCPOLARITY_HIGH;
  if (HAL_LPTIM_OC_ConfigChannel(&hlptim4, &sConfig1, LPTIM_CHANNEL_1) != HAL_OK)
  {
    Error_Handler();
  }

}

static void MX_LPUART1_UART_Init(void)
{

  hlpuart1.Instance = LPUART1;
  hlpuart1.Init.BaudRate = 209700;
  hlpuart1.Init.WordLength = UART_WORDLENGTH_8B;
  hlpuart1.Init.StopBits = UART_STOPBITS_1;
  hlpuart1.Init.Parity = UART_PARITY_NONE;
  hlpuart1.Init.Mode = UART_MODE_TX_RX;
  hlpuart1.Init.HwFlowCtl = UART_HWCONTROL_NONE;
  hlpuart1.Init.OneBitSampling = UART_ONE_BIT_SAMPLE_DISABLE;
  hlpuart1.Init.ClockPrescaler = UART_PRESCALER_DIV1;
  hlpuart1.AdvancedInit.AdvFeatureInit = UART_ADVFEATURE_NO_INIT;
  hlpuart1.FifoMode = UART_FIFOMODE_DISABLE;
  if (HAL_UART_Init(&hlpuart1) != HAL_OK)
  {
    Error_Handler();
  }
  if (HAL_UARTEx_SetTxFifoThreshold(&hlpuart1, UART_TXFIFO_THRESHOLD_1_8) != HAL_OK)
  {
    Error_Handler();
  }
  if (HAL_UARTEx_SetRxFifoThreshold(&hlpuart1, UART_RXFIFO_THRESHOLD_1_8) != HAL_OK)
  {
    Error_Handler();
  }
  if (HAL_UARTEx_DisableFifoMode(&hlpuart1) != HAL_OK)
  {
    Error_Handler();
  }
  if (HAL_RS485Ex_Init(&hlpuart1, UART_DE_POLARITY_HIGH, 0, 0) != HAL_OK)
  {
    Error_Handler();
  }

}

static void MX_UART4_Init(void)
{

  huart4.Instance = UART4;
  huart4.Init.BaudRate = 115200;
  huart4.Init.WordLength = UART_WORDLENGTH_8B;
  huart4.Init.StopBits = UART_STOPBITS_1;
  huart4.Init.Parity = UART_PARITY_NONE;
  huart4.Init.Mode = UART_MODE_TX_RX;
  huart4.Init.HwFlowCtl = UART_HWCONTROL_NONE;
  huart4.Init.OverSampling = UART_OVERSAMPLING_16;
  huart4.Init.OneBitSampling = UART_ONE_BIT_SAMPLE_DISABLE;
  huart4.Init.ClockPrescaler = UART_PRESCALER_DIV1;
  huart4.AdvancedInit.AdvFeatureInit = UART_ADVFEATURE_NO_INIT;
  if (HAL_UART_Init(&huart4) != HAL_OK)
  {
    Error_Handler();
  }
  if (HAL_UARTEx_SetTxFifoThreshold(&huart4, UART_TXFIFO_THRESHOLD_1_8) != HAL_OK)
  {
    Error_Handler();
  }
  if (HAL_UARTEx_SetRxFifoThreshold(&huart4, UART_RXFIFO_THRESHOLD_1_8) != HAL_OK)
  {
    Error_Handler();
  }
  if (HAL_UARTEx_DisableFifoMode(&huart4) != HAL_OK)
  {
    Error_Handler();
  }

}

static void MX_UART5_Init(void)
{

  huart5.Instance = UART5;
  huart5.Init.BaudRate = 115200;
  huart5.Init.WordLength = UART_WORDLENGTH_8B;
  huart5.Init.StopBits = UART_STOPBITS_1;
  huart5.Init.Parity = UART_PARITY_NONE;
  huart5.Init.Mode = UART_MODE_TX_RX;
  huart5.Init.HwFlowCtl = UART_HWCONTROL_NONE;
  huart5.Init.OverSampling = UART_OVERSAMPLING_16;
  huart5.Init.OneBitSampling = UART_ONE_BIT_SAMPLE_DISABLE;
  huart5.Init.ClockPrescaler = UART_PRESCALER_DIV1;
  huart5.AdvancedInit.AdvFeatureInit = UART_ADVFEATURE_NO_INIT;
  if (HAL_RS485Ex_Init(&huart5, UART_DE_POLARITY_HIGH, 0, 0) != HAL_OK)
  {
    Error_Handler();
  }
  if (HAL_UARTEx_SetTxFifoThreshold(&huart5, UART_TXFIFO_THRESHOLD_1_8) != HAL_OK)
  {
    Error_Handler();
  }
  if (HAL_UARTEx_SetRxFifoThreshold(&huart5, UART_RXFIFO_THRESHOLD_1_8) != HAL_OK)
  {
    Error_Handler();
  }
  if (HAL_UARTEx_DisableFifoMode(&huart5) != HAL_OK)
  {
    Error_Handler();
  }

}

static void MX_USART1_UART_Init(void)
{

  huart1.Instance = USART1;
  huart1.Init.BaudRate = 115200;
  huart1.Init.WordLength = UART_WORDLENGTH_8B;
  huart1.Init.StopBits = UART_STOPBITS_1;
  huart1.Init.Parity = UART_PARITY_NONE;
  huart1.Init.Mode = UART_MODE_TX_RX;
  huart1.Init.HwFlowCtl = UART_HWCONTROL_NONE;
  huart1.Init.OverSampling = UART_OVERSAMPLING_16;
  huart1.Init.OneBitSampling = UART_ONE_BIT_SAMPLE_DISABLE;
  huart1.Init.ClockPrescaler = UART_PRESCALER_DIV1;
  huart1.AdvancedInit.AdvFeatureInit = UART_ADVFEATURE_NO_INIT;
  if (HAL_UART_Init(&huart1) != HAL_OK)
  {
    Error_Handler();
  }
  if (HAL_UARTEx_SetTxFifoThreshold(&huart1, UART_TXFIFO_THRESHOLD_1_8) != HAL_OK)
  {
    Error_Handler();
  }
  if (HAL_UARTEx_SetRxFifoThreshold(&huart1, UART_RXFIFO_THRESHOLD_1_8) != HAL_OK)
  {
    Error_Handler();
  }
  if (HAL_UARTEx_DisableFifoMode(&huart1) != HAL_OK)
  {
    Error_Handler();
  }

}

static void MX_USART2_UART_Init(void)
{

  huart2.Instance = USART2;
  huart2.Init.BaudRate = 115200;
  huart2.Init.WordLength = UART_WORDLENGTH_8B;
  huart2.Init.StopBits = UART_STOPBITS_1;
  huart2.Init.Parity = UART_PARITY_NONE;
  huart2.Init.Mode = UART_MODE_TX_RX;
  huart2.Init.HwFlowCtl = UART_HWCONTROL_NONE;
  huart2.Init.OverSampling = UART_OVERSAMPLING_16;
  huart2.Init.OneBitSampling = UART_ONE_BIT_SAMPLE_DISABLE;
  huart2.Init.ClockPrescaler = UART_PRESCALER_DIV1;
  huart2.AdvancedInit.AdvFeatureInit = UART_ADVFEATURE_NO_INIT;
  if (HAL_UART_Init(&huart2) != HAL_OK)
  {
    Error_Handler();
  }
  if (HAL_UARTEx_SetTxFifoThreshold(&huart2, UART_TXFIFO_THRESHOLD_1_8) != HAL_OK)
  {
    Error_Handler();
  }
  if (HAL_UARTEx_SetRxFifoThreshold(&huart2, UART_RXFIFO_THRESHOLD_1_8) != HAL_OK)
  {
    Error_Handler();
  }
  if (HAL_UARTEx_DisableFifoMode(&huart2) != HAL_OK)
  {
    Error_Handler();
  }

}

static void MX_USART3_UART_Init(void)
{

  huart3.Instance = USART3;
  huart3.Init.BaudRate = 115200;
  huart3.Init.WordLength = UART_WORDLENGTH_8B;
  huart3.Init.StopBits = UART_STOPBITS_1;
  huart3.Init.Parity = UART_PARITY_NONE;
  huart3.Init.Mode = UART_MODE_TX_RX;
  huart3.Init.HwFlowCtl = UART_HWCONTROL_NONE;
  huart3.Init.OverSampling = UART_OVERSAMPLING_16;
  huart3.Init.OneBitSampling = UART_ONE_BIT_SAMPLE_DISABLE;
  huart3.Init.ClockPrescaler = UART_PRESCALER_DIV1;
  huart3.AdvancedInit.AdvFeatureInit = UART_ADVFEATURE_NO_INIT;
  if (HAL_UART_Init(&huart3) != HAL_OK)
  {
    Error_Handler();
  }
  if (HAL_UARTEx_SetTxFifoThreshold(&huart3, UART_TXFIFO_THRESHOLD_1_8) != HAL_OK)
  {
    Error_Handler();
  }
  if (HAL_UARTEx_SetRxFifoThreshold(&huart3, UART_RXFIFO_THRESHOLD_1_8) != HAL_OK)
  {
    Error_Handler();
  }
  if (HAL_UARTEx_DisableFifoMode(&huart3) != HAL_OK)
  {
    Error_Handler();
  }

}

static void MX_OCTOSPI1_Init(void)
{

  /* OCTOSPI1 parameter configuration*/
  hxspi1.Instance = OCTOSPI1;
  hxspi1.Init.FifoThresholdByte = 1;
  hxspi1.Init.MemoryMode = HAL_XSPI_SINGLE_MEM;
  hxspi1.Init.MemoryType = HAL_XSPI_MEMTYPE_MICRON;
  hxspi1.Init.MemorySize = HAL_XSPI_SIZE_32MB;
  hxspi1.Init.ChipSelectHighTimeCycle = 1;
  hxspi1.Init.FreeRunningClock = HAL_XSPI_FREERUNCLK_DISABLE;
  hxspi1.Init.ClockMode = HAL_XSPI_CLOCK_MODE_3;
  hxspi1.Init.WrapSize = HAL_XSPI_WRAP_NOT_SUPPORTED;
  hxspi1.Init.ClockPrescaler = 0;
  hxspi1.Init.SampleShifting = HAL_XSPI_SAMPLE_SHIFT_NONE;
  hxspi1.Init.DelayHoldQuarterCycle = HAL_XSPI_DHQC_DISABLE;
  hxspi1.Init.ChipSelectBoundary = HAL_XSPI_BONDARYOF_NONE;
  hxspi1.Init.DelayBlockBypass = HAL_XSPI_DELAY_BLOCK_BYPASS;
  hxspi1.Init.Refresh = 0;
  if (HAL_XSPI_Init(&hxspi1) != HAL_OK)
  {
    Error_Handler();
  }

}

static void MX_RTC_Init(void)
{

  RTC_PrivilegeStateTypeDef privilegeState = {0};

  /** Initialize RTC Only
  */
  hrtc.Instance = RTC;
  hrtc.Init.HourFormat = RTC_HOURFORMAT_24;
  hrtc.Init.AsynchPrediv = 127;
  hrtc.Init.SynchPrediv = 255;
  hrtc.Init.OutPut = RTC_OUTPUT_DISABLE;
  hrtc.Init.OutPutRemap = RTC_OUTPUT_REMAP_NONE;
  hrtc.Init.OutPutPolarity = RTC_OUTPUT_POLARITY_HIGH;
  hrtc.Init.OutPutType = RTC_OUTPUT_TYPE_OPENDRAIN;
  hrtc.Init.OutPutPullUp = RTC_OUTPUT_PULLUP_NONE;
  hrtc.Init.BinMode = RTC_BINARY_NONE;
  if (HAL_RTC_Init(&hrtc) != HAL_OK)
  {
    Error_Handler();
  }
  privilegeState.rtcPrivilegeFull = RTC_PRIVILEGE_FULL_NO;
  privilegeState.backupRegisterPrivZone = RTC_PRIVILEGE_BKUP_ZONE_NONE;
  privilegeState.backupRegisterStartZone2 = RTC_BKP_DR0;
  privilegeState.backupRegisterStartZone3 = RTC_BKP_DR0;
  if (HAL_RTCEx_PrivilegeModeSet(&hrtc, &privilegeState) != HAL_OK)
  {
    Error_Handler();
  }

  /** Enable the WakeUp
  */
  if (HAL_RTCEx_SetWakeUpTimer_IT(&hrtc, 29, RTC_WAKEUPCLOCK_CK_SPRE_16BITS, 0) != HAL_OK)
  {
    Error_Handler();
  }

}

static void MX_SPI1_Init(void)
{

  SPI_AutonomousModeConfTypeDef HAL_SPI_AutonomousMode_Cfg_Struct = {0};

  /* SPI1 parameter configuration*/
  hspi1.Instance = SPI1;
  hspi1.Init.Mode = SPI_MODE_MASTER;
  hspi1.Init.Direction = SPI_DIRECTION_1LINE;
  hspi1.Init.DataSize = SPI_DATASIZE_8BIT;
  hspi1.Init.CLKPolarity = SPI_POLARITY_LOW;
  hspi1.Init.CLKPhase = SPI_PHASE_1EDGE;
  hspi1.Init.NSS = SPI_NSS_HARD_OUTPUT;
  hspi1.Init.BaudRatePrescaler = SPI_BAUDRATEPRESCALER_2;
  hspi1.Init.FirstBit = SPI_FIRSTBIT_MSB;
  hspi1.Init.TIMode = SPI_TIMODE_DISABLE;
  hspi1.Init.CRCCalculation = SPI_CRCCALCULATION_DISABLE;
  hspi1.Init.CRCPolynomial = 0x7;
  hspi1.Init.NSSPMode = SPI_NSS_PULSE_ENABLE;
  hspi1.Init.NSSPolarity = SPI_NSS_POLARITY_LOW;
  hspi1.Init.FifoThreshold = SPI_FIFO_THRESHOLD_01DATA;
  hspi1.Init.MasterSSIdleness = SPI_MASTER_SS_IDLENESS_00CYCLE;
  hspi1.Init.MasterInterDataIdleness = SPI_MASTER_INTERDATA_IDLENESS_00CYCLE;
  hspi1.Init.MasterReceiverAutoSusp = SPI_MASTER_RX_AUTOSUSP_DISABLE;
  hspi1.Init.MasterKeepIOState = SPI_MASTER_KEEP_IO_STATE_DISABLE;
  hspi1.Init.IOSwap = SPI_IO_SWAP_DISABLE;
  hspi1.Init.ReadyMasterManagement = SPI_RDY_MASTER_MANAGEMENT_INTERNALLY;
  hspi1.Init.ReadyPolarity = SPI_RDY_POLARITY_HIGH;
  if (HAL_SPI_Init(&hspi1) != HAL_OK)
  {
    Error_Handler();
  }
  HAL_SPI_AutonomousMode_Cfg_Struct.TriggerState = SPI_AUTO_MODE_DISABLE;
  HAL_SPI_AutonomousMode_Cfg_Struct.TriggerSelection = SPI_GRP1_GPDMA_CH0_TCF_TRG;
  HAL_SPI_AutonomousMode_Cfg_Struct.TriggerPolarity = SPI_TRIG_POLARITY_RISING;
  if (HAL_SPIEx_SetConfigAutonomousMode(&hspi1, &HAL_SPI_AutonomousMode_Cfg_Struct) != HAL_OK)
  {
    Error_Handler();
  }

}

static void MX_SPI2_Init(void)
{

  SPI_AutonomousModeConfTypeDef HAL_SPI_AutonomousMode_Cfg_Struct = {0};

  /* SPI2 parameter configuration*/
  hspi2.Instance = SPI2;
  hspi2.Init.Mode = SPI_MODE_MASTER;
  hspi2.Init.Direction = SPI_DIRECTION_2LINES;
  hspi2.Init.DataSize = SPI_DATASIZE_4BIT;
  hspi2.Init.CLKPolarity = SPI_POLARITY_LOW;
  hspi2.Init.CLKPhase = SPI_PHASE_1EDGE;
  hspi2.Init.NSS = SPI_NSS_HARD_OUTPUT;
  hspi2.Init.BaudRatePrescaler = SPI_BAUDRATEPRESCALER_2;
  hspi2.Init.FirstBit = SPI_FIRSTBIT_MSB;
  hspi2.Init.TIMode = SPI_TIMODE_DISABLE;
  hspi2.Init.CRCCalculation = SPI_CRCCALCULATION_DISABLE;
  hspi2.Init.CRCPolynomial = 0x7;
  hspi2.Init.NSSPMode = SPI_NSS_PULSE_ENABLE;
  hspi2.Init.NSSPolarity = SPI_NSS_POLARITY_LOW;
  hspi2.Init.FifoThreshold = SPI_FIFO_THRESHOLD_01DATA;
  hspi2.Init.MasterSSIdleness = SPI_MASTER_SS_IDLENESS_00CYCLE;
  hspi2.Init.MasterInterDataIdleness = SPI_MASTER_INTERDATA_IDLENESS_00CYCLE;
  hspi2.Init.MasterReceiverAutoSusp = SPI_MASTER_RX_AUTOSUSP_DISABLE;
  hspi2.Init.MasterKeepIOState = SPI_MASTER_KEEP_IO_STATE_DISABLE;
  hspi2.Init.IOSwap = SPI_IO_SWAP_DISABLE;
  hspi2.Init.ReadyMasterManagement = SPI_RDY_MASTER_MANAGEMENT_INTERNALLY;
  hspi2.Init.ReadyPolarity = SPI_RDY_POLARITY_HIGH;
  if (HAL_SPI_Init(&hspi2) != HAL_OK)
  {
    Error_Handler();
  }
  HAL_SPI_AutonomousMode_Cfg_Struct.TriggerState = SPI_AUTO_MODE_DISABLE;
  HAL_SPI_AutonomousMode_Cfg_Struct.TriggerSelection = SPI_GRP1_GPDMA_CH0_TCF_TRG;
  HAL_SPI_AutonomousMode_Cfg_Struct.TriggerPolarity = SPI_TRIG_POLARITY_RISING;
  if (HAL_SPIEx_SetConfigAutonomousMode(&hspi2, &HAL_SPI_AutonomousMode_Cfg_Struct) != HAL_OK)
  {
    Error_Handler();
  }

}

static void MX_SPI4_Init(void)
{

  SPI_AutonomousModeConfTypeDef HAL_SPI_AutonomousMode_Cfg_Struct = {0};

  /* SPI4 parameter configuration*/
  hspi4.Instance = SPI4;
  hspi4.Init.Mode = SPI_MODE_MASTER;
  hspi4.Init.Direction = SPI_DIRECTION_2LINES;
  hspi4.Init.DataSize = SPI_DATASIZE_8BIT;
  hspi4.Init.CLKPolarity = SPI_POLARITY_LOW;
  hspi4.Init.CLKPhase = SPI_PHASE_1EDGE;
  hspi4.Init.NSS = SPI_NSS_SOFT;
  hspi4.Init.BaudRatePrescaler = SPI_BAUDRATEPRESCALER_2;
  hspi4.Init.FirstBit = SPI_FIRSTBIT_MSB;
  hspi4.Init.TIMode = SPI_TIMODE_DISABLE;
  hspi4.Init.CRCCalculation = SPI_CRCCALCULATION_DISABLE;
  hspi4.Init.CRCPolynomial = 0x7;
  hspi4.Init.NSSPMode = SPI_NSS_PULSE_ENABLE;
  hspi4.Init.NSSPolarity = SPI_NSS_POLARITY_LOW;
  hspi4.Init.FifoThreshold = SPI_FIFO_THRESHOLD_01DATA;
  hspi4.Init.MasterSSIdleness = SPI_MASTER_SS_IDLENESS_00CYCLE;
  hspi4.Init.MasterInterDataIdleness = SPI_MASTER_INTERDATA_IDLENESS_00CYCLE;
  hspi4.Init.MasterReceiverAutoSusp = SPI_MASTER_RX_AUTOSUSP_DISABLE;
  hspi4.Init.MasterKeepIOState = SPI_MASTER_KEEP_IO_STATE_DISABLE;
  hspi4.Init.IOSwap = SPI_IO_SWAP_DISABLE;
  hspi4.Init.ReadyMasterManagement = SPI_RDY_MASTER_MANAGEMENT_INTERNALLY;
  hspi4.Init.ReadyPolarity = SPI_RDY_POLARITY_HIGH;
  if (HAL_SPI_Init(&hspi4) != HAL_OK)
  {
    Error_Handler();
  }
  HAL_SPI_AutonomousMode_Cfg_Struct.TriggerState = SPI_AUTO_MODE_DISABLE;
  HAL_SPI_AutonomousMode_Cfg_Struct.TriggerSelection = SPI_GRP1_GPDMA_CH0_TCF_TRG;
  HAL_SPI_AutonomousMode_Cfg_Struct.TriggerPolarity = SPI_TRIG_POLARITY_RISING;
  if (HAL_SPIEx_SetConfigAutonomousMode(&hspi4, &HAL_SPI_AutonomousMode_Cfg_Struct) != HAL_OK)
  {
    Error_Handler();
  }

}

static void MX_TIM1_Init(void)
{

  TIM_ClockConfigTypeDef sClockSourceConfig = {0};
  TIM_MasterConfigTypeDef sMasterConfig = {0};

  htim1.Instance = TIM1;
  htim1.Init.Prescaler = 23;
  htim1.Init.CounterMode = TIM_COUNTERMODE_UP;
  htim1.Init.Period = 4999;
  htim1.Init.ClockDivision = TIM_CLOCKDIVISION_DIV1;
  htim1.Init.RepetitionCounter = 599;
  htim1.Init.AutoReloadPreload = TIM_AUTORELOAD_PRELOAD_DISABLE;
  if (HAL_TIM_Base_Init(&htim1) != HAL_OK)
  {
    Error_Handler();
  }
  sClockSourceConfig.ClockSource = TIM_CLOCKSOURCE_INTERNAL;
  if (HAL_TIM_ConfigClockSource(&htim1, &sClockSourceConfig) != HAL_OK)
  {
    Error_Handler();
  }
  sMasterConfig.MasterOutputTrigger = TIM_TRGO_RESET;
  sMasterConfig.MasterOutputTrigger2 = TIM_TRGO2_RESET;
  sMasterConfig.MasterSlaveMode = TIM_MASTERSLAVEMODE_DISABLE;
  if (HAL_TIMEx_MasterConfigSynchronization(&htim1, &sMasterConfig) != HAL_OK)
  {
    Error_Handler();
  }
  /* USER CODE BEGIN TIM1_Init 2 */

  // /* Internal references used by asymmetric CH1 and CH3. */
  // LL_TIM_OC_SetMode(TIM1, LL_TIM_CHANNEL_CH2, LL_TIM_OCMODE_PWM1);
  // LL_TIM_OC_SetMode(TIM1, LL_TIM_CHANNEL_CH4, LL_TIM_OCMODE_PWM1);

  /* USER CODE END TIM1_Init 2 */

}

static void MX_TIM2_Init(void)
{

  TIM_Encoder_InitTypeDef sConfig = {0};
  TIM_MasterConfigTypeDef sMasterConfig = {0};

  htim2.Instance = TIM2;
  htim2.Init.Prescaler = 0;
  htim2.Init.CounterMode = TIM_COUNTERMODE_UP;
  htim2.Init.Period = 4294967295;
  htim2.Init.ClockDivision = TIM_CLOCKDIVISION_DIV1;
  htim2.Init.AutoReloadPreload = TIM_AUTORELOAD_PRELOAD_DISABLE;
  sConfig.EncoderMode = TIM_ENCODERMODE_TI1;
  sConfig.IC1Polarity = TIM_ICPOLARITY_RISING;
  sConfig.IC1Selection = TIM_ICSELECTION_DIRECTTI;
  sConfig.IC1Prescaler = TIM_ICPSC_DIV1;
  sConfig.IC1Filter = 0;
  sConfig.IC2Polarity = TIM_ICPOLARITY_RISING;
  sConfig.IC2Selection = TIM_ICSELECTION_DIRECTTI;
  sConfig.IC2Prescaler = TIM_ICPSC_DIV1;
  sConfig.IC2Filter = 0;
  if (HAL_TIM_Encoder_Init(&htim2, &sConfig) != HAL_OK)
  {
    Error_Handler();
  }
  sMasterConfig.MasterOutputTrigger = TIM_TRGO_RESET;
  sMasterConfig.MasterSlaveMode = TIM_MASTERSLAVEMODE_DISABLE;
  if (HAL_TIMEx_MasterConfigSynchronization(&htim2, &sMasterConfig) != HAL_OK)
  {
    Error_Handler();
  }

}

static void MX_TIM3_Init(void)
{

  TIM_Encoder_InitTypeDef sConfig = {0};
  TIM_MasterConfigTypeDef sMasterConfig = {0};

  htim3.Instance = TIM3;
  htim3.Init.Prescaler = 0;
  htim3.Init.CounterMode = TIM_COUNTERMODE_UP;
  htim3.Init.Period = 4294967295;
  htim3.Init.ClockDivision = TIM_CLOCKDIVISION_DIV1;
  htim3.Init.AutoReloadPreload = TIM_AUTORELOAD_PRELOAD_DISABLE;
  sConfig.EncoderMode = TIM_ENCODERMODE_TI1;
  sConfig.IC1Polarity = TIM_ICPOLARITY_RISING;
  sConfig.IC1Selection = TIM_ICSELECTION_DIRECTTI;
  sConfig.IC1Prescaler = TIM_ICPSC_DIV1;
  sConfig.IC1Filter = 0;
  sConfig.IC2Polarity = TIM_ICPOLARITY_RISING;
  sConfig.IC2Selection = TIM_ICSELECTION_DIRECTTI;
  sConfig.IC2Prescaler = TIM_ICPSC_DIV1;
  sConfig.IC2Filter = 0;
  if (HAL_TIM_Encoder_Init(&htim3, &sConfig) != HAL_OK)
  {
    Error_Handler();
  }
  sMasterConfig.MasterOutputTrigger = TIM_TRGO_RESET;
  sMasterConfig.MasterSlaveMode = TIM_MASTERSLAVEMODE_DISABLE;
  if (HAL_TIMEx_MasterConfigSynchronization(&htim3, &sMasterConfig) != HAL_OK)
  {
    Error_Handler();
  }

}

static void MX_TIM4_Init(void)
{

  TIM_MasterConfigTypeDef sMasterConfig = {0};
  TIM_OC_InitTypeDef sConfigOC = {0};

  htim4.Instance = TIM4;
  htim4.Init.Prescaler = 0;
  htim4.Init.CounterMode = TIM_COUNTERMODE_UP;
  htim4.Init.Period = 4294967295;
  htim4.Init.ClockDivision = TIM_CLOCKDIVISION_DIV1;
  htim4.Init.AutoReloadPreload = TIM_AUTORELOAD_PRELOAD_DISABLE;
  if (HAL_TIM_PWM_Init(&htim4) != HAL_OK)
  {
    Error_Handler();
  }
  sMasterConfig.MasterOutputTrigger = TIM_TRGO_RESET;
  sMasterConfig.MasterSlaveMode = TIM_MASTERSLAVEMODE_DISABLE;
  if (HAL_TIMEx_MasterConfigSynchronization(&htim4, &sMasterConfig) != HAL_OK)
  {
    Error_Handler();
  }
  sConfigOC.OCMode = TIM_OCMODE_PWM1;
  sConfigOC.Pulse = 0;
  sConfigOC.OCPolarity = TIM_OCPOLARITY_HIGH;
  sConfigOC.OCFastMode = TIM_OCFAST_DISABLE;
  if (HAL_TIM_PWM_ConfigChannel(&htim4, &sConfigOC, TIM_CHANNEL_2) != HAL_OK)
  {
    Error_Handler();
  }
  HAL_TIM_MspPostInit(&htim4);

}

static void MX_TIM8_Init(void)
{

  TIM_MasterConfigTypeDef sMasterConfig = {0};
  TIM_OC_InitTypeDef sConfigOC = {0};
  TIM_BreakDeadTimeConfigTypeDef sBreakDeadTimeConfig = {0};

  htim8.Instance = TIM8;
  htim8.Init.Prescaler = 0;
  htim8.Init.CounterMode = TIM_COUNTERMODE_UP;
  htim8.Init.Period = 65535;
  htim8.Init.ClockDivision = TIM_CLOCKDIVISION_DIV1;
  htim8.Init.RepetitionCounter = 0;
  htim8.Init.AutoReloadPreload = TIM_AUTORELOAD_PRELOAD_DISABLE;
  if (HAL_TIM_PWM_Init(&htim8) != HAL_OK)
  {
    Error_Handler();
  }
  sMasterConfig.MasterOutputTrigger = TIM_TRGO_RESET;
  sMasterConfig.MasterOutputTrigger2 = TIM_TRGO2_RESET;
  sMasterConfig.MasterSlaveMode = TIM_MASTERSLAVEMODE_DISABLE;
  if (HAL_TIMEx_MasterConfigSynchronization(&htim8, &sMasterConfig) != HAL_OK)
  {
    Error_Handler();
  }
  sConfigOC.OCMode = TIM_OCMODE_PWM1;
  sConfigOC.Pulse = 0;
  sConfigOC.OCPolarity = TIM_OCPOLARITY_HIGH;
  sConfigOC.OCNPolarity = TIM_OCNPOLARITY_HIGH;
  sConfigOC.OCFastMode = TIM_OCFAST_DISABLE;
  sConfigOC.OCIdleState = TIM_OCIDLESTATE_RESET;
  sConfigOC.OCNIdleState = TIM_OCNIDLESTATE_RESET;
  if (HAL_TIM_PWM_ConfigChannel(&htim8, &sConfigOC, TIM_CHANNEL_1) != HAL_OK)
  {
    Error_Handler();
  }
  if (HAL_TIM_PWM_ConfigChannel(&htim8, &sConfigOC, TIM_CHANNEL_2) != HAL_OK)
  {
    Error_Handler();
  }
  sBreakDeadTimeConfig.OffStateRunMode = TIM_OSSR_DISABLE;
  sBreakDeadTimeConfig.OffStateIDLEMode = TIM_OSSI_DISABLE;
  sBreakDeadTimeConfig.LockLevel = TIM_LOCKLEVEL_OFF;
  sBreakDeadTimeConfig.DeadTime = 0;
  sBreakDeadTimeConfig.BreakState = TIM_BREAK_DISABLE;
  sBreakDeadTimeConfig.BreakPolarity = TIM_BREAKPOLARITY_HIGH;
  sBreakDeadTimeConfig.BreakFilter = 0;
  sBreakDeadTimeConfig.BreakAFMode = TIM_BREAK_AFMODE_INPUT;
  sBreakDeadTimeConfig.Break2State = TIM_BREAK2_DISABLE;
  sBreakDeadTimeConfig.Break2Polarity = TIM_BREAK2POLARITY_HIGH;
  sBreakDeadTimeConfig.Break2Filter = 0;
  sBreakDeadTimeConfig.Break2AFMode = TIM_BREAK_AFMODE_INPUT;
  sBreakDeadTimeConfig.AutomaticOutput = TIM_AUTOMATICOUTPUT_DISABLE;
  if (HAL_TIMEx_ConfigBreakDeadTime(&htim8, &sBreakDeadTimeConfig) != HAL_OK)
  {
    Error_Handler();
  }
  HAL_TIM_MspPostInit(&htim8);

}

static void MX_GPIO_Init(void)
{
  GPIO_InitTypeDef GPIO_InitStruct = {0};

  /* GPIO Ports Clock Enable */
  __HAL_RCC_GPIOE_CLK_ENABLE();
  __HAL_RCC_GPIOC_CLK_ENABLE();
  __HAL_RCC_GPIOF_CLK_ENABLE();
  __HAL_RCC_GPIOA_CLK_ENABLE();
  __HAL_RCC_GPIOB_CLK_ENABLE();
  __HAL_RCC_GPIOD_CLK_ENABLE();
  __HAL_RCC_GPIOG_CLK_ENABLE();

  /*Configure GPIO pin Output Level */
  HAL_GPIO_WritePin(GPIOF, GPIO_PIN_3|GPIO_PIN_5, GPIO_PIN_RESET);

  /*Configure GPIO pins : PC13 PC7 PC9 */
  GPIO_InitStruct.Pin = GPIO_PIN_13|GPIO_PIN_7|GPIO_PIN_9;
  GPIO_InitStruct.Mode = GPIO_MODE_ANALOG;
  GPIO_InitStruct.Pull = GPIO_NOPULL;
  HAL_GPIO_Init(GPIOC, &GPIO_InitStruct);

  /*Configure GPIO pin : PF2 */
  GPIO_InitStruct.Pin = GPIO_PIN_2;
  GPIO_InitStruct.Mode = GPIO_MODE_ANALOG;
  GPIO_InitStruct.Pull = GPIO_NOPULL;
  HAL_GPIO_Init(GPIOF, &GPIO_InitStruct);

  /*Configure GPIO pins : PF3 PF5 */
  GPIO_InitStruct.Pin = GPIO_PIN_3|GPIO_PIN_5;
  GPIO_InitStruct.Mode = GPIO_MODE_OUTPUT_PP;
  GPIO_InitStruct.Pull = GPIO_NOPULL;
  GPIO_InitStruct.Speed = GPIO_SPEED_FREQ_LOW;
  HAL_GPIO_Init(GPIOF, &GPIO_InitStruct);

  /*Configure GPIO pins : PA6 PA11 PA12 */
  GPIO_InitStruct.Pin = GPIO_PIN_6|GPIO_PIN_11|GPIO_PIN_12;
  GPIO_InitStruct.Mode = GPIO_MODE_ANALOG;
  GPIO_InitStruct.Pull = GPIO_NOPULL;
  HAL_GPIO_Init(GPIOA, &GPIO_InitStruct);

  /*Configure GPIO pins : PD10 PD1 PD4 */
  GPIO_InitStruct.Pin = GPIO_PIN_10|GPIO_PIN_1|GPIO_PIN_4;
  GPIO_InitStruct.Mode = GPIO_MODE_ANALOG;
  GPIO_InitStruct.Pull = GPIO_NOPULL;
  HAL_GPIO_Init(GPIOD, &GPIO_InitStruct);

  /*Configure GPIO pins : PG3 PG5 PG8 */
  GPIO_InitStruct.Pin = GPIO_PIN_3|GPIO_PIN_5|GPIO_PIN_8;
  GPIO_InitStruct.Mode = GPIO_MODE_ANALOG;
  GPIO_InitStruct.Pull = GPIO_NOPULL;
  HAL_GPIO_Init(GPIOG, &GPIO_InitStruct);

  /*Configure GPIO pin : PE0 */
  GPIO_InitStruct.Pin = GPIO_PIN_0;
  GPIO_InitStruct.Mode = GPIO_MODE_ANALOG;
  GPIO_InitStruct.Pull = GPIO_NOPULL;
  HAL_GPIO_Init(GPIOE, &GPIO_InitStruct);

}

void Error_Handler(void)
{
  __disable_irq();
  while (1)
  {
  }
}
